AUTOSAR XML (schema 00047)
package /System
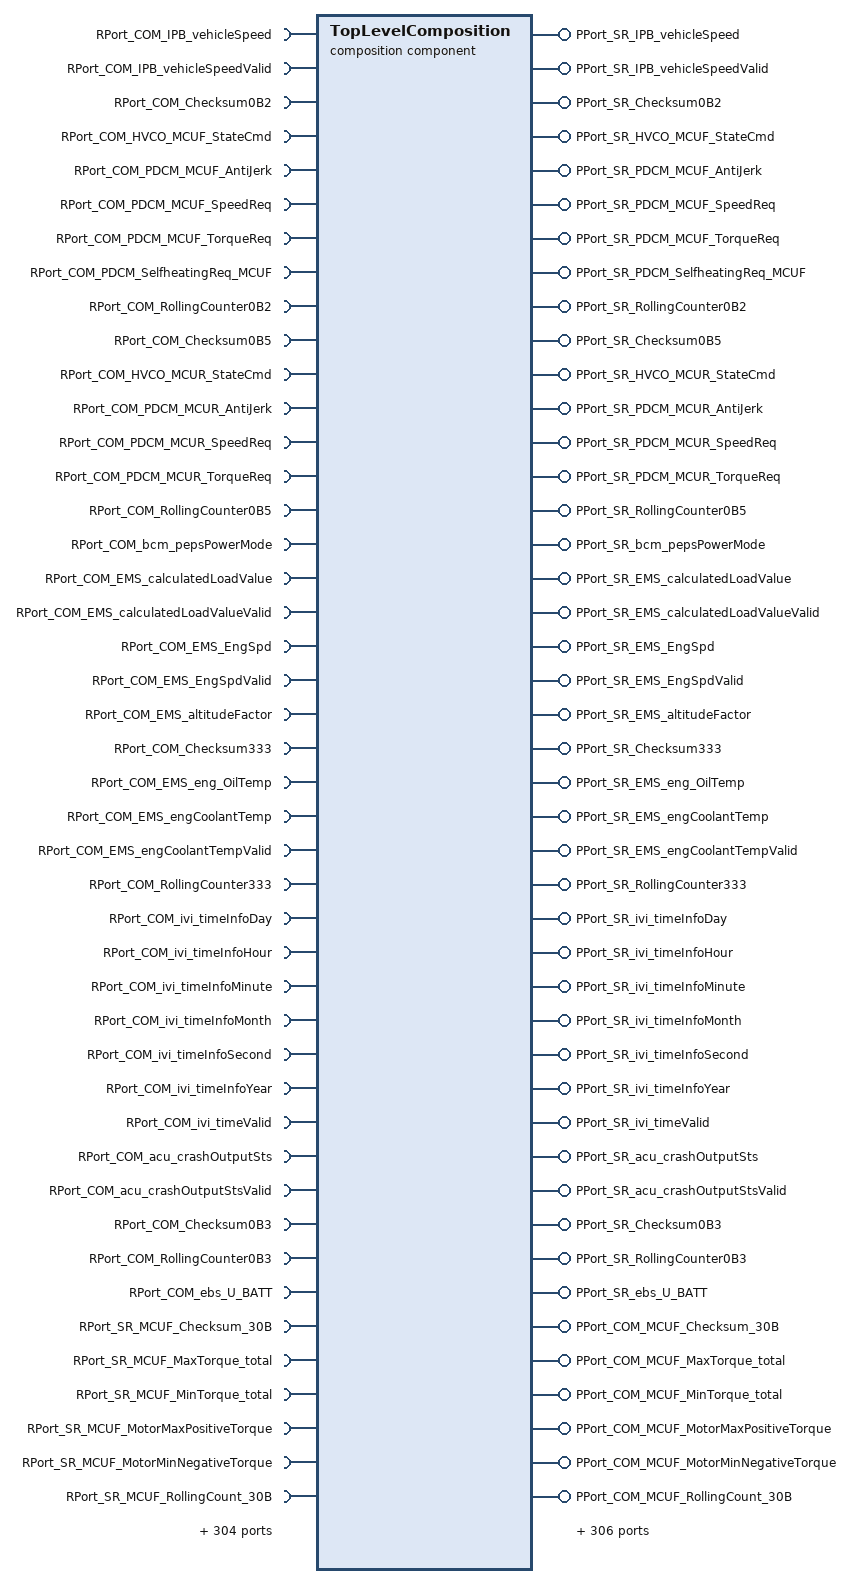
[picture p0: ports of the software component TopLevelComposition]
  composition sw component type TopLevelComposition
    378 x require port, all with nonqueued-receiver-com-spec=init-value=0:
      RPort_COM_IPB_vehicleSpeed
      RPort_COM_IPB_vehicleSpeedValid
      RPort_COM_Checksum0B2
      RPort_COM_HVCO_MCUF_StateCmd
      RPort_COM_PDCM_MCUF_AntiJerk
      RPort_COM_PDCM_MCUF_SpeedReq
      RPort_COM_PDCM_MCUF_TorqueReq
      RPort_COM_PDCM_SelfheatingReq_MCUF
      RPort_COM_RollingCounter0B2
      RPort_COM_Checksum0B5
      RPort_COM_HVCO_MCUR_StateCmd
      RPort_COM_PDCM_MCUR_AntiJerk
      RPort_COM_PDCM_MCUR_SpeedReq
      RPort_COM_PDCM_MCUR_TorqueReq
      RPort_COM_RollingCounter0B5
      RPort_COM_bcm_pepsPowerMode
      RPort_COM_EMS_calculatedLoadValue
      RPort_COM_EMS_calculatedLoadValueValid
      RPort_COM_EMS_EngSpd
      RPort_COM_EMS_EngSpdValid
      RPort_COM_EMS_altitudeFactor
      RPort_COM_Checksum333
      RPort_COM_EMS_eng_OilTemp
      RPort_COM_EMS_engCoolantTemp
      RPort_COM_EMS_engCoolantTempValid
      RPort_COM_RollingCounter333
      RPort_COM_ivi_timeInfoDay
      RPort_COM_ivi_timeInfoHour
      RPort_COM_ivi_timeInfoMinute
      RPort_COM_ivi_timeInfoMonth
      RPort_COM_ivi_timeInfoSecond
      RPort_COM_ivi_timeInfoYear
      RPort_COM_ivi_timeValid
      RPort_COM_acu_crashOutputSts
      RPort_COM_acu_crashOutputStsValid
      RPort_COM_Checksum0B3
      RPort_COM_RollingCounter0B3
      RPort_COM_ebs_U_BATT
      RPort_SR_MCUF_Checksum_30B
      RPort_SR_MCUF_MaxTorque_total
      RPort_SR_MCUF_MinTorque_total
      RPort_SR_MCUF_MotorMaxPositiveTorque
      RPort_SR_MCUF_MotorMinNegativeTorque
      RPort_SR_MCUF_RollingCount_30B
      RPort_COM_PDCM_AccelPedal_Position
      RPort_COM_PDCM_OBD_DenoGeneral
      RPort_COM_PDCM_OBD_DenoGenValid
      RPort_COM_PDCM_OBD_FaultClrInhibit
      RPort_COM_PDCM_OBD_PDTCClrSts
      RPort_COM_PDCM_OBD_WarmCycleSts
      RPort_COM_PDCM_OBD_DenoSpecial
      RPort_COM_PDCM_OBD_DenoSpecValid
      RPort_COM_PDCM_SelfheatingMode
      RPort_COM_PDCM_SOC
      RPort_COM_Checksum2C8
      RPort_COM_HV_Network_active
      RPort_COM_HV_Network_Fault
      RPort_COM_PDCM_AccelPedal_Status
      RPort_COM_PDCM_AccelPedal_Valid
      RPort_COM_PDCM_actualGear
      RPort_COM_PDCM_actualGearValid
      RPort_COM_PDCM_DriveReady
      RPort_COM_PDCM_VehicleSpeed
      RPort_COM_RollingCounter2C8
      RPort_COM_Checksum0B9
      RPort_COM_HVCO_ActiveDischarge_Req
      RPort_COM_HVCO_EmergencyShutdown_Req
      RPort_COM_PDCM_Dcy_valid
      RPort_COM_PDCM_DrivingCycle
      RPort_COM_PDCM_Max_Voltage
      RPort_COM_PDCM_Min_Voltage
      RPort_COM_RollingCounter0B9
      RPort_COM_Checksum3D7
      RPort_COM_PDCM_MCUF_MaxPower_D
      RPort_COM_PDCM_MCUF_MaxPower_G
      RPort_COM_PDCM_MCUR_MaxPower_D
      RPort_COM_PDCM_MCUR_MaxPower_G
      RPort_COM_RollingCounter3D7
      RPort_COM_HVCM_ChargeState
      RPort_COM_Checksum4FE
      RPort_COM_RollingCounter4FE
      RPort_COM_tbox_vehicleMode
      RPort_COM_ivi_altitude
      RPort_COM_PDCM_GCU_MaxPower_D
      RPort_COM_HVEM_HV_Req
      RPort_COM_HVEM_Power_Aux
      RPort_COM_HVEM_Current_HVAux
      RPort_COM_PDCM_GCU_MaxPower_G
      RPort_COM_PDCM_SelfheatingReq_MCUR
      RPort_COM_PDCM_OBD_FaultClrReq
      RPort_COM_PDCM_targetGearValid
      RPort_COM_PDCM_targetGear
      RPort_COM_PDCM_BrakePedal_Valid
      RPort_COM_PDCM_BrakePedal_Status
      RPort_COM_PDCM_BrakePedal_PressRemind
      RPort_COM_PDCM_APADrvAst_allow
      RPort_COM_PDCM_ACCDrvAst_allow
      RPort_COM_PDCM_Gear_intervention
      RPort_COM_PDCM_EVMode_Status
      RPort_COM_PDCM_driveMode
      RPort_COM_PDCM_authenticationResult
      RPort_COM_PDCM_EngIdleTgtSpd
      RPort_COM_PDCM_ClutchCommandTransferTorque
      RPort_COM_PDCM_ClutchCommand
      RPort_COM_HVCM_ChargeSpeed
      RPort_COM_HVCM_ChargeSpeed_Unit
      RPort_COM_HVCM_maxChargeSOC
      RPort_COM_HVCM_RestchargingTime
      RPort_COM_HVCM_ChargeSpeed_Valid
      RPort_COM_HVCM_RestchargingTime_Valid
      RPort_COM_HVCM_VehicleHold_Req
      RPort_COM_HVCM_AWC_AssemblyStatus
      RPort_COM_HVCM_Charge_Req
      RPort_COM_HVCM_ChargePlugUnlock_Req
      RPort_COM_HVCM_HV_Req
      RPort_COM_IPB_absActive
      RPort_COM_IPB_absFault
      RPort_COM_IPB_vdcActive
      RPort_COM_IPB_tcsActive
      RPort_COM_IPB_avhSts
      RPort_COM_IPB_avhAvailable
      RPort_COM_IPB_cdpActive
      RPort_COM_IPB_cdpAvailable
      RPort_COM_IPB_hdcAvailable
      RPort_COM_IPB_epbRequest
      RPort_COM_IPB_vehicleStandstill
      RPort_COM_IPB_vehicleStandstillValid
      RPort_COM_IPB_ModeSts
      RPort_COM_IPB_brakelightRequest
      RPort_COM_IPB_hdcSts
      RPort_COM_IPB_hhcActive
      RPort_COM_IPB_hhcAvailable
      RPort_COM_IPB_ebdFault
      RPort_COM_IPB_ebd_active
      RPort_COM_IPB_ESCoffSts
      RPort_COM_IPB_escFault
      RPort_COM_IPB_haz_active
      RPort_COM_IPB_hazErrorSt
      RPort_COM_IPB_hba_active
      RPort_COM_IPB_dtcActive
      RPort_COM_IPB_esclampdisplay
      RPort_COM_IPB_BDWActive
      RPort_COM_IPB_HRBActive
      RPort_COM_RollingCounter0A0
      RPort_COM_Checksum0A0
      RPort_COM_eps_sasSteeringAngle
      RPort_COM_eps_sasSteeringAngleValid
      RPort_COM_bcm_fuelCapSts
      RPort_COM_BCM_refuelReq
      RPort_COM_bcm_hoodSts
      RPort_COM_rls_lightSWReason
      RPort_COM_ic_oilPercent
      RPort_COM_IC_OilSensorResistance
      RPort_COM_ic_oilPercentFail
      RPort_COM_AC_ambientTempValid
      RPort_COM_AC_WarmWindReq
      RPort_COM_AC_WarmvalveReq
      RPort_COM_AC_ambientTemp
      RPort_COM_ic_totalMileage
      RPort_COM_ic_totalMileageValid
      RPort_COM_LgtA
      RPort_COM_LgtAValSts
      RPort_COM_EPBS_Sts
      RPort_COM_EPBS_BrakeSwInfo
      RPort_COM_RollingCounter202
      RPort_COM_Checksum202
      RPort_COM_EPBS_FaultLamp
      RPort_COM_TBOX_OTAEnergyCtl
      RPort_COM_TBOX_OTATimeSet
      RPort_COM_bcm_IMMOReleaseIndication
      RPort_COM_bcm_pepsKeyNotInCarInd
      RPort_COM_bcm_keyValid
      RPort_COM_bcm_pepsKeySerchFailInd
      RPort_COM_bcm_pepsKeyCloserInd
      RPort_COM_bcm_pepsFobLowBatWarning
      RPort_COM_bcm_pepsPowerRelayErrWarning
      RPort_COM_bcm_IndicationPressBrake
      RPort_COM_bcm_LowFrequencyAntennaFault
      RPort_COM_BCM_RainWinowCloseWarning
      RPort_COM_bcm_remoteMode
      RPort_COM_bcm_ble_response
      RPort_COM_BCM_RKEWindowCmd
      RPort_COM_bcm_srSsAndWindowsEnable
      RPort_COM_bcm_rke_fuelPortCapOpenCtrl
      RPort_COM_bcm_pepsKeyInCarInd
      RPort_COM_bcm_tbox_response
      RPort_COM_bcm_approachingUnlockFedb
      RPort_COM_bcm_12VBatterySOC
      RPort_COM_BCM_sunroofGlassCmd
      RPort_COM_bcm_followMeHomeFedb
      RPort_COM_bcm_awayLockFeedback
      RPort_COM_bcm_PepsKeyIncarIndi
      RPort_COM_RollingCounter2C1
      RPort_COM_Checksum2C1
      RPort_COM_EMS_TargetIdleEngSpd
      RPort_COM_EMS_StartAllowed
      RPort_COM_EMS_StopAllowed
      RPort_COM_EMS_engStartfailure
      RPort_COM_EMS_EngRunningStatusValid
      RPort_COM_EMS_EngRunningStatus
      RPort_COM_RollingCounter083
      RPort_COM_Checksum083
      RPort_COM_EMS_DrivingCycle
      RPort_COM_EMS_Fault_Code
      RPort_COM_EMS_ToltalFaultNum
      RPort_COM_EMS_FuelCharingSts
      RPort_COM_EMS_relifValveOpenState
      RPort_COM_EMS_Warmvalvestate
      RPort_COM_RollingCounter305
      RPort_COM_Checksum305
      RPort_COM_EMS_thermostat_valve
      RPort_COM_EMS_catalystWarmupsta
      RPort_COM_EMS_engStartCoolantTemp
      RPort_COM_EMS_SystemErrorLevel
      RPort_SR_MCUF_UdFreq
      RPort_SR_MCUF_UdVolt
      RPort_SR_MCUF_BusFreq
      Rport_SR_MCUF_BusCurrent
      RPort_SR_Checksum0A1
      RPort_SR_RollingCounter0A1
      RPort_SR_MCUF_SelfheatingMode
      RPort_SR_MCUF_SelfheatingAllow
      RPort_SR_MCUF_MotorPower
      RPort_SR_MCUF_MotorSpd
      RPort_SR_MCUF_MotorSpdValid
      RPort_SR_MCUF_ActualTorque
      RPort_SR_Checksum0A2
      RPort_SR_MCUF_Actual_Voltage
      RPort_SR_MCUF_AS_Activ
      RPort_SR_MCUF_Current_HV
      RPort_SR_MCUF_Fault_ASC
      RPort_SR_MCUF_Fault_ShutOff_HV_Req
      RPort_SR_MCUF_MotorMaxSpd
      RPort_SR_MCUF_State
      RPort_SR_MCUF_TMReq_ASC
      RPort_SR_RollingCounter0A2
      RPort_SR_Checksum351
      RPort_SR_MCUF_ControllerTemp
      RPort_SR_MCUF_Motor_Current_Phase_A
      RPort_SR_MCUF_Motor_Current_Phase_B
      RPort_SR_MCUF_Motor_Current_Phase_C
      RPort_SR_MCUF_MotorTemp
      RPort_SR_RollingCounter351
      RPort_SR_Checksum315
      RPort_SR_MCUF_Fault_ActiveDischarge
      RPort_SR_MCUF_Fault_Code
      RPort_SR_MCUF_Fault_PowerDerating
      RPort_SR_MCUF_FaultLamp_Req
      RPort_SR_MCUF_MotorStatus
      RPort_SR_MCUF_OBD_Lamp_Req
      RPort_SR_MCUF_PerInd_MaxPower
      RPort_SR_MCUF_PerInd_MaxTorque
      RPort_SR_MCUF_Status_ActiveDischarge
      RPort_SR_MCUF_ToltalFaultNum
      RPort_SR_RollingCounter315
      RPort_SR_Checksum415
      RPort_SR_MCUF_Derating_OverTemp
      RPort_SR_MCUF_Efficiency
      RPort_SR_MCUF_HV_Voltg_Free
      RPort_SR_MCUF_HW_Version
      RPort_SR_MCUF_RTM_OverCurrent
      RPort_SR_MCUF_RTM_OverSpeed
      RPort_SR_MCUF_RTM_OverTemp_EM
      RPort_SR_MCUF_RTM_OverTemp_MCU
      RPort_SR_MCUF_RTM_WarnComm
      RPort_SR_MCUF_SW_Major_Version
      RPort_SR_MCUF_SW_Minor_Version
      RPort_SR_MCUF_Vehicle_Type
      RPort_SR_RollingCounter415
      RPort_SR_GCU_GeneratorDCVolt
      RPort_SR_GCU_GeneratorDCCurrent
      RPort_SR_GCU_GeneratorMaxSpd
      RPort_SR_GCU_GeneratorSt
      RPort_SR_GCU_Fault_PowerDerating
      RPort_SR_GCU_FaultCode
      RPort_SR_GCU_Fault_ShutOff_HV_Req
      RPort_SR_RollingCounter335
      RPort_SR_Checksum335
      RPort_SR_GCU_ActualTorque
      RPort_SR_GCU_GeneratorSpd
      RPort_SR_GCU_GeneratorSpdValid
      RPort_SR_GCU_State
      RPort_SR_GCU_MotorPower
      RPort_SR_RollingCounter0A7
      RPort_SR_Checksum0A7
      RPort_SR_GCU_GeneratorMaxPositiveTorque
      RPort_SR_GCU_GeneratorMinNegativeTorque
      RPort_SR_GCU_MaxTorque_total
      RPort_SR_GCU_MinTorque_total
      RPort_SR_GCU_HV_Voltg_Free
      RPort_SR_RollingCounter337
      RPort_SR_Checksum337
      RPort_SR_GCU_ControllerTemp
      RPort_SR_GCU_MotorTemp
      RPort_SR_GCU_GeneratorFaultLamp
      RPort_SR_GCU_OBD_Lamp_Req
      RPort_SR_GCU_ActiveDischargeState
      RPort_SR_RollingCounter360
      RPort_SR_Checksum360
      RPort_SR_TCU_CrankingAuthorizationEnable
      RPort_SR_TCU_Clutch_Status
      RPort_SR_TCU_GearEngagementAvailable
      RPort_SR_TCU_ClutchAvailableMaximumTorque
      RPort_SR_TCU_ClutchAvailableMinimumTorque
      RPort_SR_TCU_ClutchCapacityAct
      RPort_SR_RollingCounter095
      RPort_SR_Checksum095
      RPort_SR_TCU_MaxFrtMotPwr_Req
      RPort_SR_TCU_Fault_Reaction_Req
      RPort_SR_TCU_MaxGCUPwr_Req
      RPort_SR_RollingCounter097
      RPort_SR_Checksum097
      RPort_SR_TCU_OBD_Lamp_Req
      RPort_SR_TCU_FaultLamp_Req
      RPort_SR_TCU_TransmissionFluidTemp
      RPort_SR_TCU_AirFlowRequest
      RPort_SR_RollingCounter331
      RPort_SR_Checksum331
      RPort_COM_EMS_FrictionTorque
      RPort_COM_EMS_FuelcutAllowed
      RPort_COM_EMS_EngineFuelCutOff
      RPort_COM_EMS_engIdleCtrlState
      RPort_COM_EMS_EngineSpeedLimitation
      RPort_COM_EMS_EngineOverSpeed
      RPort_COM_EMS_Workpoint_Req
      RPort_COM_EMS_EngFlywh
      RPort_COM_RollingCounter086
      RPort_COM_Checksum086
      RPort_COM_PDCM_GCU_TorqueReq
      RPort_COM_PDCM_GCU_SpeedReq
      RPort_COM_PDCM_GCU_Torque_Ref
      RPort_COM_HVCO_GCU_StateCmd
      RPort_COM_RollingCounter0BA
      RPort_COM_Checksum0BA
      RPort_SR_MCUF_FaultData{0..15}
      RPort_SR_GCU_FaultData{0..15}
      RRort_COM_IPB_wheelSpeedRL
      RRort_COM_IPB_wheelSpeedRLValid
      RRort_COM_IPB_wheelSpeedRR
      RRort_COM_IPB_wheelSpeedRRValid
      RRort_COM_RollingCounter122
      RRort_COM_Checksum122
      RRort_COM_IPB_wheelSpeedFL
      RRort_COM_IPB_wheelSpeedFLValid
      RRort_COM_IPB_wheelSpeedFR
      RRort_COM_IPB_wheelSpeedFRValid
      RRort_COM_RollingCounter142
      RRort_COM_Checksum142
    350 x provide port, all with nonqueued-sender-com-spec=init-value=0:
      PPort_SR_IPB_vehicleSpeed
      PPort_SR_IPB_vehicleSpeedValid
      PPort_SR_Checksum0B2
      PPort_SR_HVCO_MCUF_StateCmd
      PPort_SR_PDCM_MCUF_AntiJerk
      PPort_SR_PDCM_MCUF_SpeedReq
      PPort_SR_PDCM_MCUF_TorqueReq
      PPort_SR_PDCM_SelfheatingReq_MCUF
      PPort_SR_RollingCounter0B2
      PPort_SR_Checksum0B5
      PPort_SR_HVCO_MCUR_StateCmd
      PPort_SR_PDCM_MCUR_AntiJerk
      PPort_SR_PDCM_MCUR_SpeedReq
      PPort_SR_PDCM_MCUR_TorqueReq
      PPort_SR_RollingCounter0B5
      PPort_SR_bcm_pepsPowerMode
      PPort_SR_EMS_calculatedLoadValue
      PPort_SR_EMS_calculatedLoadValueValid
      PPort_SR_EMS_EngSpd
      PPort_SR_EMS_EngSpdValid
      PPort_SR_EMS_altitudeFactor
      PPort_SR_Checksum333
      PPort_SR_EMS_eng_OilTemp
      PPort_SR_EMS_engCoolantTemp
      PPort_SR_EMS_engCoolantTempValid
      PPort_SR_RollingCounter333
      PPort_SR_ivi_timeInfoDay
      PPort_SR_ivi_timeInfoHour
      PPort_SR_ivi_timeInfoMinute
      PPort_SR_ivi_timeInfoMonth
      PPort_SR_ivi_timeInfoSecond
      PPort_SR_ivi_timeInfoYear
      PPort_SR_ivi_timeValid
      PPort_SR_acu_crashOutputSts
      PPort_SR_acu_crashOutputStsValid
      PPort_SR_Checksum0B3
      PPort_SR_RollingCounter0B3
      PPort_SR_ebs_U_BATT
      PPort_COM_MCUF_Checksum_30B
      PPort_COM_MCUF_MaxTorque_total
      PPort_COM_MCUF_MinTorque_total
      PPort_COM_MCUF_MotorMaxPositiveTorque
      PPort_COM_MCUF_MotorMinNegativeTorque
      PPort_COM_MCUF_RollingCount_30B
      PPort_SR_PDCM_AccelPedal_Position
      PPort_SR_PDCM_OBD_DenoGeneral
      PPort_SR_PDCM_OBD_DenoGenValid
      PPort_SR_PDCM_OBD_DenoSpecial
      PPort_SR_PDCM_OBD_DenoSpecValid
      PPort_SR_PDCM_OBD_FaultClrInhibit
      PPort_SR_PDCM_OBD_PDTCClrSts
      PPort_SR_PDCM_OBD_WarmCycleSts
      PPort_SR_PDCM_SelfheatingMode
      PPort_SR_PDCM_SOC
      PPort_SR_Checksum2C8
      PPort_SR_HV_Network_active
      PPort_SR_HV_Network_Fault
      PPort_SR_PDCM_AccelPedal_Status
      PPort_SR_PDCM_AccelPedal_Valid
      PPort_SR_PDCM_actualGear
      PPort_SR_PDCM_actualGearValid
      PPort_SR_PDCM_DriveReady
      PPort_SR_PDCM_VehicleSpeed
      PPort_SR_RollingCounter2C8
      PPort_SR_Checksum0B9
      PPort_SR_HVCO_ActiveDischarge_Req
      PPort_SR_HVCO_EmergencyShutdown_Req
      PPort_SR_PDCM_Dcy_valid
      PPort_SR_PDCM_DrivingCycle
      PPort_SR_PDCM_Max_Voltage
      PPort_SR_PDCM_Min_Voltage
      PPort_SR_RollingCounter0B9
      PPort_SR_Checksum3D7
      PPort_SR_PDCM_MCUF_MaxPower_D
      PPort_SR_PDCM_MCUF_MaxPower_G
      PPort_SR_PDCM_MCUR_MaxPower_D
      PPort_SR_PDCM_MCUR_MaxPower_G
      PPort_SR_RollingCounter3D7
      PPort_SR_HVCM_ChargeState
      PPort_SR_Checksum4FE
      PPort_SR_RollingCounter4FE
      PPort_SR_tbox_vehicleMode
      PPort_SR_ivi_altitude
      PPort_SR_PDCM_GCU_MaxPower_D
      PPort_SR_HVEM_HV_Req
      PPort_SR_HVEM_Power_Aux
      PPort_SR_HVEM_Current_HVAux
      PPort_SR_PDCM_GCU_MaxPower_G
      PPort_SR_PDCM_SelfheatingReq_MCUR
      PPort_SR_PDCM_OBD_FaultClrReq
      PPort_SR_PDCM_targetGearValid
      PPort_SR_PDCM_targetGear
      PPort_SR_PDCM_BrakePedal_Valid
      PPort_SR_PDCM_BrakePedal_Status
      PPort_SR_PDCM_BrakePedal_PressRemind
      PPort_SR_PDCM_APADrvAst_allow
      PPort_SR_PDCM_ACCDrvAst_allow
      PPort_SR_PDCM_Gear_intervention
      PPort_SR_PDCM_EVMode_Status
      PPort_SR_PDCM_driveMode
      PPort_SR_PDCM_authenticationResult
      PPort_SR_PDCM_EngIdleTgtSpd
      PPort_SR_PDCM_ClutchCommandTransferTorque
      PPort_SR_PDCM_ClutchCommand
      PPort_SR_HVCM_ChargeSpeed
      PPort_SR_HVCM_ChargeSpeed_Unit
      PPort_SR_HVCM_maxChargeSOC
      PPort_SR_HVCM_RestchargingTime
      PPort_SR_HVCM_ChargeSpeed_Valid
      PPort_SR_HVCM_RestchargingTime_Valid
      PPort_SR_HVCM_VehicleHold_Req
      PPort_SR_HVCM_AWC_AssemblyStatus
      PPort_SR_HVCM_Charge_Req
      PPort_SR_HVCM_ChargePlugUnlock_Req
      PPort_SR_HVCM_HV_Req
      PPort_SR_IPB_absActive
      PPort_SR_IPB_absFault
      PPort_SR_IPB_vdcActive
      PPort_SR_IPB_avhSts
      PPort_SR_IPB_tcsActive
      PPort_SR_IPB_avhAvailable
      PPort_SR_IPB_cdpActive
      PPort_SR_IPB_cdpAvailable
      PPort_SR_IPB_hdcAvailable
      PPort_SR_IPB_epbRequest
      PPort_SR_IPB_vehicleStandstill
      PPort_SR_IPB_vehicleStandstillValid
      PPort_SR_IPB_ModeSts
      PPort_SR_IPB_brakelightRequest
      PPort_SR_IPB_hdcSts
      PPort_SR_IPB_hhcActive
      PPort_SR_IPB_hhcAvailable
      PPort_SR_IPB_ebdFault
      PPort_SR_IPB_ebd_active
      PPort_SR_IPB_ESCoffSts
      PPort_SR_IPB_escFault
      PPort_SR_IPB_haz_active
      PPort_SR_IPB_hazErrorSt
      PPort_SR_IPB_esclampdisplay
      PPort_SR_IPB_BDWActive
      PPort_SR_IPB_hba_active
      PPort_SR_IPB_dtcActive
      PPort_SR_IPB_HRBActive
      PPort_SR_RollingCounter0A0
      PPort_SR_Checksum0A0
      PPort_SR_eps_sasSteeringAngle
      PPort_SR_eps_sasSteeringAngleValid
      PPort_SR_bcm_fuelCapSts
      PPort_SR_BCM_refuelReq
      PPort_SR_bcm_hoodSts
      PPort_SR_rls_lightSWReason
      PPort_SR_ic_oilPercent
      PPort_SR_IC_OilSensorResistance
      PPort_SR_AC_WarmWindReq
      PPort_SR_AC_ambientTempValid
      PPort_SR_ic_oilPercentFail
      PPort_SR_AC_WarmvalveReq
      PPort_SR_AC_ambientTemp
      PPort_SR_ic_totalMileage
      PPort_SR_ic_totalMileageValid
      PPort_SR_LgtA
      PPort_SR_LgtAValSts
      PPort_SR_EPBS_FaultLamp
      PPort_SR_EPBS_Sts
      PPort_SR_EPBS_BrakeSwInfo
      PPort_SR_Checksum202
      PPort_SR_RollingCounter202
      PPort_SR_TBOX_OTAEnergyCtl
      PPort_SR_TBOX_OTATimeSet
      PPort_SR_bcm_IMMOReleaseIndication
      PPort_SR_bcm_pepsKeyNotInCarInd
      PPort_SR_bcm_keyValid
      PPort_SR_bcm_pepsKeySerchFailInd
      PPort_SR_bcm_pepsKeyCloserInd
      PPort_SR_bcm_pepsFobLowBatWarning
      PPort_SR_bcm_pepsPowerRelayErrWarning
      PPort_SR_bcm_IndicationPressBrake
      PPort_SR_bcm_LowFrequencyAntennaFault
      PPort_SR_BCM_RainWinowCloseWarning
      PPort_SR_bcm_remoteMode
      PPort_SR_bcm_ble_response
      PPort_SR_BCM_RKEWindowCmd
      PPort_SR_bcm_srSsAndWindowsEnable
      PPort_SR_bcm_rke_fuelPortCapOpenCtrl
      PPort_SR_bcm_pepsKeyInCarInd
      PPort_SR_bcm_tbox_response
      PPort_SR_bcm_approachingUnlockFedb
      PPort_SR_bcm_12VBatterySOC
      PPort_SR_BCM_sunroofGlassCmd
      PPort_SR_bcm_followMeHomeFedb
      PPort_SR_bcm_awayLockFeedback
      PPort_SR_bcm_PepsKeyIncarIndi
      PPort_SR_RollingCounter2C1
      PPort_SR_Checksum2C1
      PPort_SR_EMS_TargetIdleEngSpd
      PPort_SR_EMS_StartAllowed
      PPort_SR_EMS_StopAllowed
      PPort_SR_EMS_engStartfailure
      PPort_SR_EMS_EngRunningStatusValid
      PPort_SR_EMS_EngRunningStatus
      PPort_SR_RollingCounter083
      PPort_SR_Checksum083
      PPort_SR_EMS_DrivingCycle
      PPort_SR_EMS_Fault_Code
      PPort_SR_EMS_ToltalFaultNum
      PPort_SR_EMS_FuelCharingSts
      PPort_SR_EMS_relifValveOpenState
      PPort_SR_EMS_Warmvalvestate
      PPort_SR_RollingCounter305
      PPort_SR_Checksum305
      PPort_SR_EMS_thermostat_valve
      PPort_SR_EMS_catalystWarmupsta
      PPort_SR_EMS_engStartCoolantTemp
      PPort_SR_EMS_SystemErrorLevel
      PPort_COM_MCUF_UdFreq
      PPort_COM_MCUF_UdVolt
      Pport_COM_MCUF_BusFreq
      PPort_COM_MCUF_BusCurrent
      PPort_COM_Checksum0A1
      PPort_COM_RollingCounter0A1
      PPort_COM_MCUF_SelfheatingMode
      PPort_COM_MCUF_SelfheatingAllow
      PPort_COM_MCUF_ActualTorque
      PPort_COM_MCUF_MotorPower
      PPort_COM_MCUF_MotorSpdValid
      PPort_COM_MCUF_MotorSpd
      PPort_COM_Checksum0A2
      PPort_COM_MCUF_Actual_Voltage
      PPort_COM_MCUF_AS_Activ
      PPort_COM_MCUF_Current_HV
      PPort_COM_MCUF_Fault_ASC
      PPort_COM_MCUF_Fault_ShutOff_HV_Req
      PPort_COM_MCUF_MotorMaxSpd
      PPort_COM_MCUF_State
      PPort_COM_MCUF_TMReq_ASC
      PPort_COM_RollingCounter0A2
      PPort_COM_Checksum351
      PPort_COM_MCUF_ControllerTemp
      PPort_COM_MCUF_Motor_Current_Phase_A
      PPort_COM_MCUF_Motor_Current_Phase_B
      PPort_COM_MCUF_Motor_Current_Phase_C
      PPort_COM_MCUF_MotorTemp
      PPort_COM_RollingCounter351
      PPort_COM_Checksum315
      PPort_COM_MCUF_Fault_ActiveDischarge
      PPort_COM_MCUF_Fault_Code
      PPort_COM_MCUF_Fault_PowerDerating
      PPort_COM_MCUF_FaultLamp_Req
      PPort_COM_MCUF_MotorStatus
      PPort_COM_MCUF_OBD_Lamp_Req
      PPort_COM_MCUF_PerInd_MaxPower
      PPort_COM_MCUF_PerInd_MaxTorque
      PPort_COM_MCUF_Status_ActiveDischarge
      PPort_COM_MCUF_ToltalFaultNum
      PPort_COM_RollingCounter315
      PPort_COM_Checksum415
      PPort_COM_MCUF_Derating_OverTemp
      PPort_COM_MCUF_Efficiency
      PPort_COM_MCUF_HV_Voltg_Free
      PPort_COM_MCUF_HW_Version
      PPort_COM_MCUF_RTM_OverCurrent
      PPort_COM_MCUF_RTM_OverSpeed
      PPort_COM_MCUF_RTM_OverTemp_EM
      PPort_COM_MCUF_RTM_OverTemp_MCU
      PPort_COM_MCUF_RTM_WarnComm
      PPort_COM_MCUF_SW_Major_Version
      PPort_COM_MCUF_SW_Minor_Version
      PPort_COM_MCUF_Vehicle_Type
      PPort_COM_RollingCounter415
      PPort_COM_GCU_GeneratorDCVolt
      PPort_COM_GCU_GeneratorDCCurrent
      PPort_COM_GCU_GeneratorMaxSpd
      PPort_COM_GCU_GeneratorSt
      PPort_COM_GCU_Fault_PowerDerating
      PPort_COM_GCU_FaultCode
      PPort_COM_GCU_Fault_ShutOff_HV_Req
      PPort_COM_RollingCounter335
      PPort_COM_Checksum335
      PPort_COM_GCU_ActualTorque
      PPort_COM_GCU_GeneratorSpd
      PPort_COM_GCU_GeneratorSpdValid
      PPort_COM_GCU_State
      PPort_COM_GCU_MotorPower
      PPort_COM_RollingCounter0A7
      PPort_COM_Checksum0A7
      PPort_COM_GCU_GeneratorMaxPositiveTorque
      PPort_COM_GCU_GeneratorMinNegativeTorque
      PPort_COM_GCU_MaxTorque_total
      PPort_COM_GCU_MinTorque_total
      PPort_COM_GCU_HV_Voltg_Free
      PPort_COM_RollingCounter337
      PPort_COM_Checksum337
      PPort_COM_GCU_ControllerTemp
      PPort_COM_GCU_MotorTemp
      PPort_COM_GCU_GeneratorFaultLamp
      PPort_COM_GCU_OBD_Lamp_Req
      PPort_COM_GCU_ActiveDischargeState
      PPort_COM_RollingCounter360
      PPort_COM_Checksum360
      PPort_COM_TCU_CrankingAuthorizationEnable
      PPort_COM_TCU_Clutch_Status
      PPort_COM_TCU_GearEngagementAvailable
      PPort_COM_TCU_ClutchAvailableMaximumTorque
      PPort_COM_TCU_ClutchAvailableMinimumTorque
      PPort_COM_TCU_ClutchCapacityAct
      PPort_COM_RollingCounter095
      PPort_COM_Checksum095
      PPort_COM_TCU_MaxFrtMotPwr_Req
      PPort_COM_TCU_Fault_Reaction_Req
      PPort_COM_TCU_MaxGCUPwr_Req
      PPort_COM_RollingCounter097
      PPort_COM_Checksum097
      PPort_COM_TCU_OBD_Lamp_Req
      PPort_COM_TCU_FaultLamp_Req
      PPort_COM_TCU_TransmissionFluidTemp
      PPort_COM_TCU_AirFlowRequest
      PPort_COM_RollingCounter331
      PPort_COM_Checksum331
      PPort_SR_EMS_FrictionTorque
      PPort_SR_EMS_FuelcutAllowed
      PPort_SR_EMS_EngineFuelCutOff
      PPort_SR_EMS_engIdleCtrlState
      PPort_SR_EMS_EngineSpeedLimitation
      PPort_SR_EMS_EngineOverSpeed
      PPort_SR_EMS_Workpoint_Req
      PPort_SR_EMS_EngFlywh
      PPort_SR_RollingCounter086
      PPort_SR_Checksum086
      PPort_SR_PDCM_GCU_TorqueReq
      PPort_SR_PDCM_GCU_SpeedReq
      PPort_SR_PDCM_GCU_Torque_Ref
      PPort_SR_HVCO_GCU_StateCmd
      PPort_SR_RollingCounter0BA
      PPort_SR_Checksum0BA
      PPort_COM_MCUF_Inner1_FaultData
      PPort_COM_MCUF_Inner2_FaultData
      PPort_COM_GCU_Inner1_FaultData
      PPort_COM_GCU_Inner2_FaultData
      PPort_SR_IPB_wheelSpeedRL
      PPort_SR_IPB_wheelSpeedRLValid
      PPort_SR_IPB_wheelSpeedRR
      PPort_SR_IPB_wheelSpeedRRValid
      PPort_SR_RollingCounter122
      PPort_SR_Checksum122
      PPort_SR_IPB_wheelSpeedFL
      PPort_SR_IPB_wheelSpeedFLValid
      PPort_SR_IPB_wheelSpeedFR
      PPort_SR_IPB_wheelSpeedFRValid
      PPort_SR_RollingCounter142
      PPort_SR_Checksum142
    27 x component:
      CPT_CDD_CORE2: type=CDD_CORE2
      CPT_CDD_CORE1: type=CDD_CORE1
      CPT_CDD_CORE0: type=CDD_CORE0
      CPT_ASW_XCP: type=ASW_XCP
      CPT_ASW_WDG: type=ASW_WDG
      CPT_ASW_NVM: type=ASW_NVM
      CPT_ASW_NM: type=ASW_NM
      CPT_ASW_DEM: type=ASW_DEM
      CPT_ASW_DCM: type=ASW_DCM
      CPT_ASW_CORE2: type=ASW_CORE2
      CPT_ASW_CORE1: type=ASW_CORE1
      CPT_ASW_CORE0: type=ASW_CORE0
      CPT_ASW_BASE: type=ASW_BASE
      CPT_BswM: type=BswM
      CPT_Dem: type=Dem
      CPT_EcuM: type=EcuM
      CPT_WdgM: type=WdgM
      CPT_Det: type=Det
      CPT_ComM: type=ComM
      CPT_NvM: type=NvM
      CPT_rba_DiagLib: type=rba_DiagLib
      CPT_Dcm: type=Dcm
      CPT_ASW_COM: type=ASW_COM
      CPT_RSID: type=RSID
      CPT_SWC_DEM: type=SWC_DEM
      CPT_ASW_CORE3: type=ASW_CORE3
      CPT_CDD_CORE3: type=CDD_CORE3
    connect CPT_ASW_DEM.DataServices_CS_ExtendedDataRecord_Aged_counter -> CPT_Dem.DataServices_CS_ExtendedDataRecord_Aged_counter
    connect CPT_ASW_DEM.DataServices_CS_ExtendedDataRecord_Fault_pending_counter -> CPT_Dem.DataServices_CS_ExtendedDataRecord_Fault_pending_counter
    connect CPT_ASW_BASE.PPort_SwcModeRequest -> CPT_BswM.RP_BswMArbitration_BswMSwcModeRequest
    connect CPT_ASW_CORE0.PPort_TransmitData2Core1 -> CPT_ASW_CORE1.RPort_ReceiverDataFromCore0
    connect CPT_ASW_CORE1.PPort_TransmitData2Core0 -> CPT_ASW_CORE0.RPort_ReceiveDatafromCore1
    connect CPT_ASW_CORE0.PPort_SwcModeRequest -> CPT_BswM.RP_BswMArbitration_BswMSwcModeRequest
    connect CPT_CDD_CORE0.PPort_CPUUtilizationCore0 -> CPT_ASW_CORE0.RPort_CPUUtilizationCore0
    connect CPT_CDD_CORE0.PPort_GetMaxUserStackUtilization -> CPT_ASW_CORE0.RPort_GetMaxUserStackUtilization
    connect CPT_CDD_CORE1.PPort_CPUUtilizationCore1 -> CPT_ASW_CORE1.RPort_CPUUtilizationCore1
    connect CPT_CDD_CORE1.PPort_GetMaxUserStackUtilization -> CPT_ASW_CORE1.RPort_GetMaxUserStackUtilization
    connect CPT_CDD_CORE2.PPort_CPUUtilizationCore2 -> CPT_ASW_CORE2.RPort_CPUUtilizationCore2
    connect CPT_CDD_CORE2.PPort_GetMaxUserStackUtilization -> CPT_ASW_CORE2.RPort_GetMaxUserStackUtilization
    connect CPT_CDD_CORE0.PPort_Core0Server -> CPT_ASW_CORE0.RPort_ClientCallCore0
    connect CPT_Dcm.DCMServices -> CPT_ASW_DCM.RPort_DCMServices
    connect CPT_Dem.OpCycle_DemOperationCycle_Power -> CPT_ASW_DEM.RPort_OpCycle_DemOperationCycle_Power
    connect CPT_WdgM.globalMode -> CPT_ASW_WDG.RPort_WdgM_GlobalMode
    connect CPT_WdgM.localSupervision_WdgMSupervisedEntity_Alive_Supervision_Entity1_WdgMCheckpoint_Alive_Supervision_Entity1 -> CPT_ASW_WDG.RPort_Alive_Supervision_Entity1
    connect CPT_WdgM.localSupervision_WdgMSupervisedEntity_Alive_Supervision_Entity1_WdgMCheckpoint_Alive_Supervision_Entity1 -> CPT_ASW_WDG.RPort_Deadline_Supervision_Entity1
    connect CPT_ASW_NM.PP_BswMArbitration_BswM_MRP_Network -> CPT_BswM.RP_BswMArbitration_BswM_MRP_SWC_Network
    connect CPT_ASW_NM.PP_BswMArbitration_BswM_MRP_NmState -> CPT_BswM.RP_BswMArbitration_BswM_MRP_SWC_Network
    connect CPT_ComM.UR_ComMUser_Can_Network_CanNodeNum_01 -> CPT_ASW_NM.RP_ComM_UserRequest_CAN0
    connect CPT_ComM.modeLimitation -> CPT_ASW_NM.RPort_EcuModeLimitation
    connect CPT_RSID.RoutineServices_DcmDspRoutine_0203 -> CPT_Dcm.RoutineServices_DcmDspRoutine_0203
    connect CPT_ASW_DCM.VIT_04 -> CPT_Dcm.InfotypeServices_DcmDspVehInfoData_04
    connect CPT_ASW_DCM.VIT_06 -> CPT_Dcm.InfotypeServices_VIT_06_0
    connect CPT_ASW_DCM.VIT_0A -> CPT_Dcm.InfotypeServices_DcmDspVehInfoData_0A
    connect CPT_Dem.OpCycle_DemOperationCycle_Ignition -> CPT_ASW_DEM.OpCycle_DemOperationCycle_Ignition
    connect CPT_Dem.IndStatus_MIL -> CPT_ASW_DEM.IndStatus_MIL
    connect CPT_SWC_DEM.DataServices_PID_0D -> CPT_Dem.DataServices_PID_0D
    connect CPT_SWC_DEM.DataServices_PID_0C -> CPT_Dem.DataServices_PID_0C
    connect CPT_SWC_DEM.DataServices_PID_49 -> CPT_Dem.DataServices_PID_49
    connect CPT_SWC_DEM.DataServices_PID_05 -> CPT_Dem.DataServices_PID_05
    connect CPT_SWC_DEM.DataServices_PID_42 -> CPT_Dem.DataServices_PID_42
    connect CPT_SWC_DEM.DataServices_PID_04 -> CPT_Dem.DataServices_PID_04
    connect CPT_SWC_DEM.DataServices_PID_02 -> CPT_Dem.DataServices_PID_02
    connect CPT_ASW_DCM.DataServices_DcmDspPidData_30 -> CPT_Dcm.DataServices_DcmDspPidData_30
    connect CPT_ASW_DCM.DataServices_DcmDspPidData_05 -> CPT_Dcm.DataServices_DcmDspPidData_05
    connect CPT_ASW_DCM.DataServices_DcmDspPidData_0D -> CPT_Dcm.DataServices_DcmDspPidData_0D
    connect CPT_ASW_DCM.DataServices_DcmDspPidData_49 -> CPT_Dcm.DataServices_DcmDspPidData_49
    connect CPT_ASW_DCM.DataServices_DcmDspPidData_04 -> CPT_Dcm.DataServices_DcmDspPidData_04
    connect CPT_ASW_DCM.DataServices_DcmDspPidData_31 -> CPT_Dcm.DataServices_DcmDspPidData_31
    connect CPT_ASW_DCM.DataServices_DcmDspPidData_21 -> CPT_Dcm.DataServices_DcmDspPidData_21
    connect CPT_ASW_DCM.DataServices_DcmDspPidData_42 -> CPT_Dcm.DataServices_DcmDspPidData_42
    connect CPT_ASW_DCM.DataServices_DcmDspPidData_0C -> CPT_Dcm.DataServices_DcmDspPidData_0C
    connect CPT_ASW_DCM.DataServices_DcmDspPidData_41 -> CPT_Dcm.DataServices_DcmDspPidData_41
    connect CPT_NvM.NvM_NativeBlock_2 -> CPT_ASW_NVM.RPort_ASW_NVM_BlockNative_1024_1
    connect CPT_CDD_CORE3.PPort_CPUUtilizationCore3 -> CPT_ASW_CORE3.RPort_CPUUtilizationCore3
    connect CPT_CDD_CORE3.PPort_GetMaxUserStackUtilization -> CPT_ASW_CORE3.RPort_GetMaxUserStackUtilization
